# RTC_CE__Real_Time_Clock_2 register map
Vendor: Texas Instruments
Peripheral module from a debugger description file (folder msp430).
Registers are 8-bit, access not given, no defined reset value unless marked. A register's access mark holds for its fields unless they carry their own. Offsets are as the file gives them; lines under a group give offsets from that group; [hi:lo] are bit positions; {n}, {i} and the like mark numbered series; 'fields as' and 'values as' point back to an identical list; <NAME> marks a mode.

## RTC_CE_Real_Time_Clock
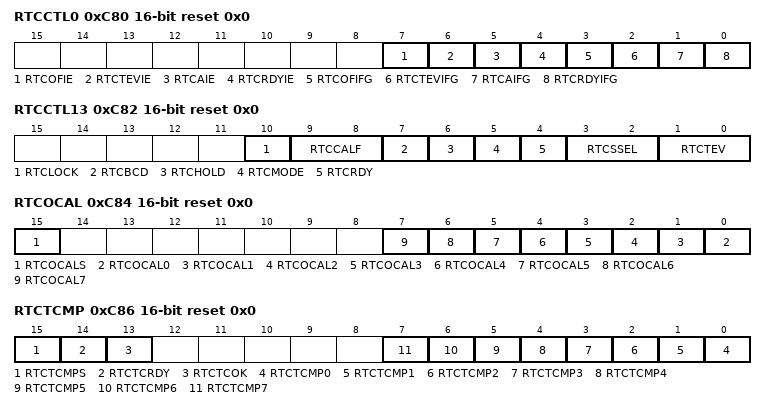
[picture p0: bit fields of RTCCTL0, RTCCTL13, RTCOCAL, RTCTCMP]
0xC80 RTCCTL0 16-bit rw reset 0x0 — Real Timer Clock Control 0/Key
  [7] RTCOFIE — RTC 32kHz cyrstal oscillator fault interrupt enable
  [6] RTCTEVIE — RTC Time Event Interrupt Enable Flag
  [5] RTCAIE — RTC Alarm Interrupt Enable Flag
  [4] RTCRDYIE — RTC Ready Interrupt Enable Flag
  [3] RTCOFIFG — RTC 32kHz cyrstal oscillator fault interrupt flag
  [2] RTCTEVIFG — RTC Time Event Interrupt Flag
  [1] RTCAIFG — RTC Alarm Interrupt Flag
  [0] RTCRDYIFG — RTC Ready Interrupt Flag
0xC82 RTCCTL13 16-bit rw reset 0x0 — Real Timer Clock Control 1/3
  [10] RTCLOCK — RTC Real-Time clock lock
  [9:8] RTCCALF — RTC Calibration Frequency Bit 1
    0=RTC Calibration Frequency: No Output; 1=RTC Calibration Frequency: 512 Hz; 2=RTC Calibration Frequency: 256 Hz; 3=RTC Calibration Frequency: 1 Hz
  [7] RTCBCD — RTC BCD 0:Binary / 1:BCD
  [6] RTCHOLD
  [5] RTCMODE — RTC Mode 0:Counter / 1: Calendar
  [4] RTCRDY — RTC Ready
  [3:2] RTCSSEL — RTC Source Select 1
    0=RTC Source Select ACLK; 1=RTC Source Select SMCLK; 2=RTC Source Select RT1PS; 3=RTC Source Select RT1PS
  [1:0] RTCTEV — RTC Time Event 1
    0=RTC Time Event: 0 (Min. changed); 1=RTC Time Event: 1 (Hour changed); 2=RTC Time Event: 2 (12:00 changed); 3=RTC Time Event: 3 (00:00 changed)
0xC84 RTCOCAL 16-bit rw reset 0x0 — Real Timer Clock Offset Calibartion
  [15] RTCOCALS — RTC Offset Calibration Sign
  [n] RTCOCAL{n} (n=0..7) — RTC Offset Calibration Bit {n}
0xC86 RTCTCMP 16-bit rw reset 0x0 — Real Timer Temperature Compensation
  [15] RTCTCMPS — RTC Temperature Compensation Sign
  [14] RTCTCRDY — RTC Temperature compensation ready
  [13] RTCTCOK — RTC Temperature compensation write OK
  [n] RTCTCMP{n} (n=0..7) — RTC Temperature Compensation Bit {n}
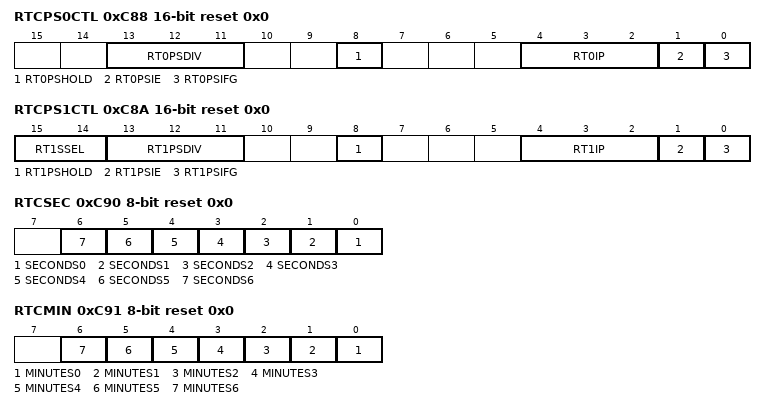
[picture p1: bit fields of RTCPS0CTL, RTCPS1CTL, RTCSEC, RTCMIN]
0xC88 RTCPS0CTL 16-bit rw reset 0x0 — Real Timer Prescale Timer 0 Control
  [13:11] RT0PSDIV — RTC Prescale Timer 0 Clock Divide Bit: 2
    0=RTC Prescale Timer 0 Clock Divide: /2; 1=RTC Prescale Timer 0 Clock Divide: /4; 2=RTC Prescale Timer 0 Clock Divide: /8; 3=RTC Prescale Timer 0 Clock Divide: /16; 4=RTC Prescale Timer 0 Clock Divide: /32; 5=RTC Prescale Timer 0 Clock Divide: /64; 6=RTC Prescale Timer 0 Clock Divide: /128; 7=RTC Prescale Timer 0 Clock Divide: /256
  [8] RT0PSHOLD — RTC Prescale Timer 0 Hold
  [4:2] RT0IP — RTC Prescale Timer 0 Interrupt Interval Bit: 2
    0=RTC Prescale Timer 0 Interrupt Interval /2; 1=RTC Prescale Timer 0 Interrupt Interval /4; 2=RTC Prescale Timer 0 Interrupt Interval /8; 3=RTC Prescale Timer 0 Interrupt Interval /16; 4=RTC Prescale Timer 0 Interrupt Interval /32; 5=RTC Prescale Timer 0 Interrupt Interval /64; 6=RTC Prescale Timer 0 Interrupt Interval /128; 7=RTC Prescale Timer 0 Interrupt Interval /256
  [1] RT0PSIE — RTC Prescale Timer 0 Interrupt Enable Flag
  [0] RT0PSIFG — RTC Prescale Timer 0 Interrupt Flag
0xC8A RTCPS1CTL 16-bit rw reset 0x0 — Real Timer Prescale Timer 1 Control
  [15:14] RT1SSEL — RTC Prescale Timer 1 Source Select Bit 1
    {v}=RTC Prescale Timer 1 Source Select: {v} (v=0..3)
  [13:11] RT1PSDIV — RTC Prescale Timer 1 Clock Divide Bit: 2
    0=RTC Prescale Timer 1 Clock Divide: /2; 1=RTC Prescale Timer 1 Clock Divide: /4; 2=RTC Prescale Timer 1 Clock Divide: /8; 3=RTC Prescale Timer 1 Clock Divide: /16; 4=RTC Prescale Timer 1 Clock Divide: /32; 5=RTC Prescale Timer 1 Clock Divide: /64; 6=RTC Prescale Timer 1 Clock Divide: /128; 7=RTC Prescale Timer 1 Clock Divide: /256
  [8] RT1PSHOLD — RTC Prescale Timer 1 Hold
  [4:2] RT1IP — RTC Prescale Timer 1 Interrupt Interval Bit: 2
    0=RTC Prescale Timer 1 Interrupt Interval /2; 1=RTC Prescale Timer 1 Interrupt Interval /4; 2=RTC Prescale Timer 1 Interrupt Interval /8; 3=RTC Prescale Timer 1 Interrupt Interval /16; 4=RTC Prescale Timer 1 Interrupt Interval /32; 5=RTC Prescale Timer 1 Interrupt Interval /64; 6=RTC Prescale Timer 1 Interrupt Interval /128; 7=RTC Prescale Timer 1 Interrupt Interval /256
  [1] RT1PSIE — RTC Prescale Timer 1 Interrupt Enable Flag
  [0] RT1PSIFG — RTC Prescale Timer 1 Interrupt Flag
0xC8C RTCPS 16-bit — Real Timer Prescale Timer Control
0xC8E RTCIV 16-bit — Real Time Clock Interrupt Vector
0xC90 RTCTIM0 16-bit — Real Time Clock Time 0
0xC90 RTCSEC rw reset 0x0 — Real Time Clock Seconds
  [n] SECONDS{n} (n=0..6) — Real Time Clock Seconds Bit: {n}
0xC91 RTCMIN rw reset 0x0 — Real Time Clock Minutes
  [n] MINUTES{n} (n=0..6) — Real Time Clock Minutes Bit: {n}
0xC92 RTCTIM1 16-bit — Real Time Clock Time 1
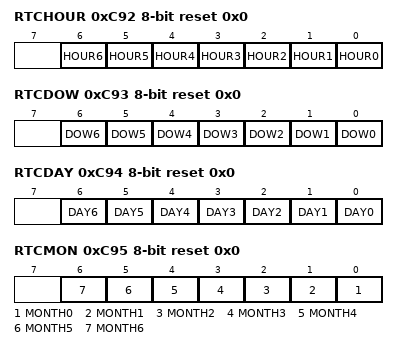
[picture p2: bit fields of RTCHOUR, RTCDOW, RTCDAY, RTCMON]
0xC92 RTCHOUR rw reset 0x0 — Real Time Clock Hour
  [n] HOUR{n} (n=0..6) — Real Time Clock Hour Bit: {n}
0xC93 RTCDOW rw reset 0x0 — Real Time Clock Day of week
  [n] DOW{n} (n=0..6) — Real Time Clock DOW Bit: {n}
0xC94 RTCDATE 16-bit — Real Time Clock Date
0xC94 RTCDAY rw reset 0x0 — Real Time Clock Day
  [n] DAY{n} (n=0..6) — Real Time Clock Day Bit: {n}
0xC95 RTCMON rw reset 0x0 — Real Time Clock Month
  [n] MONTH{n} (n=0..6) — Real Time Clock Month Bit: {n}
0xC96 RTCYEAR 16-bit — Real Time Clock Year
0xC98 RTCAMINHR 16-bit — Real Time Clock Alarm Min/Hour
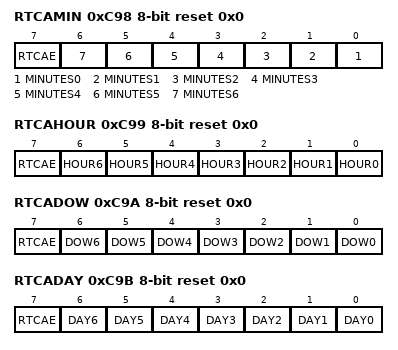
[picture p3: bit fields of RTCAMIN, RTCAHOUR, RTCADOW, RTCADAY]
0xC98 RTCAMIN rw reset 0x0 — Real Time Clock Alarm Min
  [7] RTCAE — Real Time Clock Alarm enable
  [n] MINUTES{n} (n=0..6) — Real Time Clock Minutes Bit: {n}
0xC99 RTCAHOUR rw reset 0x0 — Real Time Clock Alarm Hour
  [7] RTCAE — Real Time Clock Alarm enable
  [n] HOUR{n} (n=0..6) — Real Time Clock Hour Bit: {n}
0xC9A RTCADOWDAY 16-bit — Real Time Clock Alarm day of week/day
0xC9A RTCADOW rw reset 0x0 — Real Time Clock Alarm Day of week
  [7] RTCAE — Real Time Clock Alarm enable
  [n] DOW{n} (n=0..6) — Real Time Clock DOW Bit: {n}
0xC9B RTCADAY rw reset 0x0 — Real Time Clock Alarm Day
  [7] RTCAE — Real Time Clock Alarm enable
  [n] DAY{n} (n=0..6) — Real Time Clock Day Bit: {n}
0xC9C BIN2BCD 16-bit — Real Time Binary-to-BCD conversion register
0xC9E BCD2BIN 16-bit — Real Time BCD-to-binary conversion register
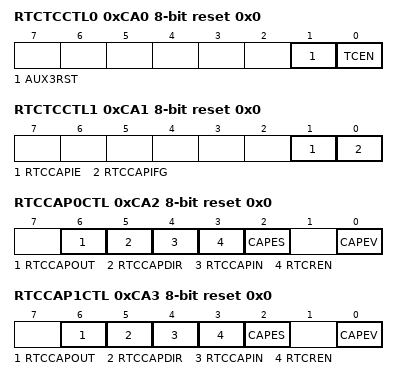
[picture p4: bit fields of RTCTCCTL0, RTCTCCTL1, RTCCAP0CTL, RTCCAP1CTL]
0xCA0 RTCTCCTL0 rw reset 0x0 — Real-Time Clock Time Capture Control Register 0
  [1] AUX3RST — RTC Indication of power cycle on AUXVCC3
  [0] TCEN — RTC Enable for RTC Tamper Detection with Time Stamp
0xCA1 RTCTCCTL1 rw reset 0x0 — Real-Time Clock Time Capture Control Register 1
  [1] RTCCAPIE — RTC Tamper Event Interrupt Enable
  [0] RTCCAPIFG — RTC Tamper Event Interrupt Flag
0xCA2 RTCCAP0CTL rw reset 0x0 — Tamper Detect Pin 0 Control Register
  [6] RTCCAPOUT — RTC RTCCAPx Output
  [5] RTCCAPDIR — RTC RTCCAPx Pin direction
  [4] RTCCAPIN — RTC RTCCAPx input
  [3] RTCREN — RTC RTCCAPx pin pullup/pulldown resistor enable
  [2] CAPES — RTC Event Edge Select
  [0] CAPEV — RTC Tamper Event Flag
0xCA3 RTCCAP1CTL rw reset 0x0 — Tamper Detect Pin 1 Control Register
  fields as RTCCAP0CTL
0xCB0 RTCSECBAK0 — Real-Time Clock Seconds Backup Register 0
0xCB1 RTCMINBAK0 — Real-Time Clock Minutes Backup Register 0
0xCB2 RTCHOURBAK0 — Real-Time Clock Hours Backup Register 0
0xCB3 RTCDAYBAK0 — Real-Time Clock Days Backup Register 0
0xCB4 RTCMONBAK0 — Real-Time Clock Months Backup Register 0
0xCB6 RTCYEARBAK0 — Real-Time Clock year Backup Register 0
0xCB8 RTCSECBAK1 — Real-Time Clock Seconds Backup Register 1
0xCB9 RTCMINBAK1 — Real-Time Clock Minutes Backup Register 1
0xCBA RTCHOURBAK1 — Real-Time Clock Hours Backup Register 1
0xCBB RTCDAYBAK1 — Real-Time Clock Days Backup Register 1
0xCBC RTCMONBAK1 — Real-Time Clock Months Backup Register 1
0xCBE RTCYEARBAK1 — Real-Time Clock Year Backup Register 1
